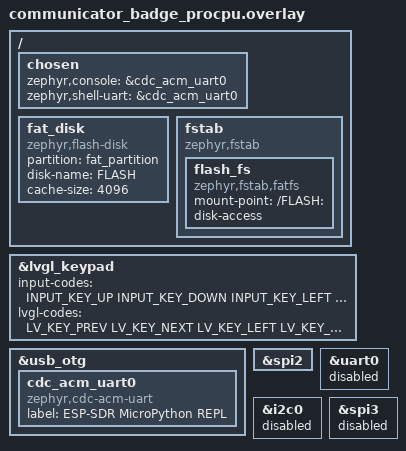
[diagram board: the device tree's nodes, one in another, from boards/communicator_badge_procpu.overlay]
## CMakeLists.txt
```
# SPDX-License-Identifier: GPL-3.0-or-later

cmake_minimum_required(VERSION 3.20.0)

# The radio is on the chip (radio.conf) except on an ESP32-P4, whose radio is the board's
# ESP32-C6 behind a link. Under sysbuild the board is not known here yet: sysbuild.cmake adds
# radio.conf there.
if(BOARD AND NOT BOARD MATCHES "/+esp32p4")
  list(APPEND EXTRA_CONF_FILE ${CMAKE_CURRENT_LIST_DIR}/radio.conf)
endif()

# MicroPython is built by its Zephyr module (CONFIG_MICROPYTHON, modules/micropython/zephyr)
# while find_package() configures Zephyr, and provides main(). The module reads two things
# from here: this app's C modules (cmod/) and, for the frozen manifests, the directory of the
# bundled apps' index. The index is written below, once Kconfig says which apps the board
# has; the module's configure-time pass over the manifest only needs the file to exist.
set(USER_C_MODULES ${CMAKE_CURRENT_LIST_DIR}/cmod)
set(MICROPY_MANIFEST_EGGS_INDEX_DIR ${CMAKE_BINARY_DIR}/eggs_index)
set(EGGS_INDEX ${MICROPY_MANIFEST_EGGS_INDEX_DIR}/eggs/__init__.py)
if(NOT EXISTS ${EGGS_INDEX})
  file(WRITE ${EGGS_INDEX} "INDEX = {}\n")
endif()

find_package(Zephyr REQUIRED HINTS $ENV{ZEPHYR_BASE})
project(esp_sdr_micropython)

# mpconfigport_esdr.h (CONFIG_MICROPY_CONFIGFILE), for the micropython library and its qstr scan.
zephyr_include_directories(src)

if(CONFIG_SOC_SERIES_ESP32C5)
  # The ESP32-C5: the REPL on the USB-Serial-JTAG console, MicroPython in the main thread
  # (the port's main()), its static heap in SRAM block 0 (sorted before the bank's snippet).
  zephyr_linker_sources(RAM_SECTIONS SORT_KEY app src/c5_low.ld)
elseif(CONFIG_SOC_SERIES_ESP32P4)
  # The ESP32-P4 (WHY2025 badge, ESP32-P4-Function-EV-Board): MicroPython in the main thread
  # (the port's main()), its heap in PSRAM (cmod/esdr_radio.c), the REPL on CDC-ACM and DFU
  # through the shared USB device on the OTG HS port, started by the port's mp_usbd_init()
  # (cmod/esdr_usb.c).
  include(${CMAKE_CURRENT_LIST_DIR}/../common/common.cmake)
  # The link to the radio and the USB glue, plain Zephyr code (outside MicroPython's include
  # path, whose assert.h hides the HAL's static_assert).
  target_sources(app PRIVATE cmod/esdr_remote.c cmod/esdr_hb.c cmod/esdr_mon.c cmod/esdr_usb.c
    cmod/esdr_gl.c)
  target_include_directories(app PRIVATE cmod ../osmosdr/src)
  # Its SDIO side, shared with the bridge app.
  include(${CMAKE_CURRENT_LIST_DIR}/../common/esdr_sdio_host.cmake)
  # The gapless stream's channelizer (cmod/esdr_gl.c): the fixed-point bank on PIE.
  include(${CMAKE_CURRENT_LIST_DIR}/../common/esdr_pfbq.cmake)
elseif(CONFIG_SOC_SERIES_ESP32)
  # The classic ESP32 (MCH2022 badge): the REPL on the console UART (the badge's RP2040 bridges
  # it to USB), MicroPython in the main thread (the port's main()), its heap in PSRAM
  # (cmod/esdr_radio.c), the radio on the chip behind the link's interface (cmod/esdr_local.c,
  # plain Zephyr code as esdr_remote.c is on the P4).
  target_sources(app PRIVATE cmod/esdr_local.c cmod/esdr_mon.c src/setjmp.S)
  target_include_directories(app PRIVATE cmod ../osmosdr/src)
  # The crystal calibration requests on the library (apps/common).
  include(${CMAKE_CURRENT_LIST_DIR}/../common/esdr_cal.cmake)
  # The ROM's setjmp spills windows by SYSCALL, as on the S3 (setjmp.S).
  zephyr_link_libraries("-Wl,--wrap=setjmp")
else()
  include(${CMAKE_CURRENT_LIST_DIR}/../common/common.cmake)

  target_sources(app PRIVATE src/boot.c src/setjmp.S src/usb_disks.c)
  # ff.h: usb_disks.c refreshes a FatFs volume without remounting it.
  target_link_libraries(app PRIVATE ELMFAT)
  # See setjmp.S.
  zephyr_link_libraries("-Wl,--wrap=setjmp")
  # boot.c runs the port's main() as real_main() in a thread of its own.
  set_property(SOURCE ${ZEPHYR_MICROPYTHON_MODULE_DIR}/ports/zephyr/main.c
               TARGET_DIRECTORY micropython APPEND PROPERTY COMPILE_DEFINITIONS main=real_main)
endif()

# What this app changes in the module's build (mpy_module.cmake).
include(${CMAKE_CURRENT_LIST_DIR}/mpy_module.cmake)
```

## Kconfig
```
# SPDX-License-Identifier: GPL-3.0-or-later

mainmenu "ESP-SDR MicroPython"

# The MicroPython symbols (CONFIG_MICROPYTHON, CONFIG_MICROPY_*) are the module's
# (modules/micropython/zephyr/Kconfig); these are the app's.
menu "ESP-SDR MicroPython"

config APP_EGGS
	string "Bundled apps"
	default ""
	help
	  The apps (folders of eggs/) the board's frozen manifest has, comma
	  separated; empty: all of them. The launcher's index lists these.

config APP_MP_STACK_SIZE
	int "MicroPython thread stack, bytes"
	default 16384
	help
	  In the SRAM above the ring banks (ESP_SDR_HIGH_RAM, about 38 KiB,
	  shared with the ring, the DAC stream and their threads).
	  Bounds the recursion depth, about 300 bytes per Python call. A
	  GUI export with LVGL peaked at 11.9 KiB.

config APP_HOME_CODE
	int "Key that goes home when held"
	default 1
	help
	  On boards whose keys drive LVGL as a keypad: the input code (Zephyr
	  input-event-codes.h) that, held 1.5 s, ends the running app and
	  shows the launcher. 1 is INPUT_KEY_ESC.

config APP_MP_PSRAM_HEAP_KB
	int "Python heap in PSRAM, KiB"
	default 5120
	help
	  Added to the internal heap at every start. Captures (file_sink) are
	  buffered here; the rest of the 8 MiB PSRAM is the Wi-Fi heap and the
	  transmit ring.

endmenu # ESP-SDR MicroPython

rsource "../common/Kconfig"

# USB device identity (VID, PID, strings) for the sample USB helper.
source "samples/subsys/usb/common/Kconfig.sample_usbd"

source "Kconfig.zephyr"
```

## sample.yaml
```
sample:
  name: ESP-SDR MicroPython
  description: >-
    MicroPython as the main program: on the XIAO ESP32S3 and the Communicator with the display,
    REPL on the USB CDC-ACM port; headless on the ESP32-C5-Zero, the bench's coordinator, REPL
    on USB-Serial-JTAG; on the WHY2025 badge's ESP32-P4 (the radio its ESP32-C6, REPL on
    CDC-ACM) and the MCH2022 badge's ESP32 (REPL on the console UART)
common:
  tags: esp-sdr
  build_only: true
tests:
  sample.esp_sdr.micropython:
    sysbuild: true
    platform_allow:
      - xiao_esp32s3/esp32s3/procpu
      - communicator_badge/esp32s3/procpu
    integration_platforms:
      - xiao_esp32s3/esp32s3/procpu
  sample.esp_sdr.micropython.c5:
    platform_allow:
      - waveshare_esp32c5_zero/esp32c5/hpcore
    integration_platforms:
      - waveshare_esp32c5_zero/esp32c5/hpcore
  sample.esp_sdr.micropython.p4:
    platform_allow:
      - why2025_badge/esp32p4/hpcore
      - esp32p4_function_ev_board/esp32p4/hpcore
    integration_platforms:
      - why2025_badge/esp32p4/hpcore
      - esp32p4_function_ev_board/esp32p4/hpcore
  sample.esp_sdr.micropython.mch2022:
    platform_allow:
      - mch2022/esp32/procpu
    integration_platforms:
      - mch2022/esp32/procpu
```

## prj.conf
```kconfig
# MicroPython (modules/micropython/ports/zephyr/prj.conf), on every board; the radio where it
# is on the chip in radio.conf; what both S3 boards add is in socs/esp32s3_procpu.conf (USB,
# PSRAM, display, the ring), what one board adds in boards/<board>.conf (the XIAO S3: SD card;
# the C5: the diagnostic-bus ring and the paced transmitter; the P4: display, keyboard, PSRAM).
CONFIG_POLL=y
CONFIG_REBOOT=y
# The port's zsensor module includes the sensor API; no sensor, no code.
CONFIG_SENSOR=y
CONFIG_HEAP_MEM_POOL_IGNORE_MIN=y

# REPL input comes from the console driver's receive hook (src/zephyr_getchar.c), output
# goes to the console UART directly.
CONFIG_SERIAL=y
CONFIG_STDOUT_CONSOLE=y
CONFIG_CONSOLE_HANDLER=y
CONFIG_UART_CONSOLE_DEBUG_SERVER_HOOKS=y
CONFIG_UART_INTERRUPT_DRIVEN=y
CONFIG_UART_USE_RUNTIME_CONFIGURE=y

# MicroPython's Zephyr module builds the port as the micropython library, which provides
# main(); paths are relative to this directory. The boards set the heap
# (CONFIG_MICROPY_HEAP_SIZE) and those without a display their manifest.
CONFIG_MICROPYTHON=y
CONFIG_MICROPY_CONFIGFILE="mpconfigport_esdr.h"
CONFIG_MICROPY_FROZEN_MODULES=y
CONFIG_MICROPY_FROZEN_MANIFEST="manifest.py"
CONFIG_MICROPY_CONFIG_ROM_LEVEL_EXTRA_FEATURES=y

# Nothing may print into the REPL: no log backend.
CONFIG_LOG=n

CONFIG_RESET_ON_FATAL_ERROR=y


# MicroPython's Zephyr port (machine_spi.c, built wherever SPI is on: both boards)
# still uses SPI_OP_MODE_MASTER, whose deprecation warning -Werror (twister, CI) makes fatal.
CONFIG_WARN_DEPRECATED=n
```

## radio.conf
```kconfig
# SPDX-License-Identifier: GPL-3.0-or-later

# The radio on the chip itself, for every board but the WHY2025 badge's ESP32-P4 (CMakeLists.txt):
# the Wi-Fi driver brings it up at boot; nothing may scan or connect.
CONFIG_NETWORKING=y
CONFIG_WIFI=y
CONFIG_ESP32_WIFI_STA_POWER_SAVE_NONE=y
# No IP traffic: the network stack only carries the Wi-Fi driver, minimal.
CONFIG_NET_IPV6=n
CONFIG_NET_IPV4=y
CONFIG_NET_PKT_RX_COUNT=4
CONFIG_NET_PKT_TX_COUNT=4
CONFIG_NET_BUF_RX_COUNT=8
CONFIG_NET_BUF_TX_COUNT=8
CONFIG_NET_RX_STACK_SIZE=1024
CONFIG_NET_L2_WIFI_SHELL=n

CONFIG_ESP_SDR=y
```

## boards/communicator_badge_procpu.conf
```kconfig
# The Hackaday Communicator badge with its display and keyboard (socs/esp32s3_procpu.conf has
# what both ESP32-S3 boards share).

# No GDMA for the display SPI (overlay): DRAM ends at the ring banks.
CONFIG_DMA=n
# LVGL reads the keyboard every refresh; 2 queued keys fit the DRAM, 4 did not.
CONFIG_LV_Z_KEYPAD_INPUT_MSGQ_COUNT=2
```

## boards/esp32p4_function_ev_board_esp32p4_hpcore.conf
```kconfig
# SPDX-License-Identifier: GPL-3.0-or-later
#
# The ESP32-P4-Function-EV-Board's ESP32-P4: MicroPython without a display, the REPL and DFU on
# the USB 2.0 OTG HS port, the Python heap in PSRAM. No radio on the chip (no radio.conf): the
# board's ESP32-C6 is the radio, over SDIO. prj.conf has what every board shares.

CONFIG_MAIN_STACK_SIZE=32768
# The port's own heap in SRAM is a token; esdr_port_init() adds the PSRAM heap.
CONFIG_MICROPY_HEAP_SIZE=16384
CONFIG_APP_MP_PSRAM_HEAP_KB=4096
CONFIG_MICROPY_FROZEN_MANIFEST="manifest_headless.py"
CONFIG_APP_EGGS="datalink"
CONFIG_FPU=y
# As on the WHY2025 badge: the SoC turns the FPU on without sharing, and the channelizer's
# thread (esdr_gl.c) preempts MicroPython in float code.
CONFIG_FPU_SHARING=y
# PSRAM (on the WHY2025 badge the display brings it in).
CONFIG_ESP_SPIRAM=y
CONFIG_HEAP_MEM_POOL_SIZE=32768

# The FAT volume /FLASH: and the SD card /SD: (overlay).
CONFIG_FLASH_MAP=y
CONFIG_FILE_SYSTEM=y
CONFIG_FAT_FILESYSTEM_ELM=y
CONFIG_DISK_DRIVER_FLASH=y
CONFIG_DISK_DRIVER_SDMMC=y
CONFIG_FS_FATFS_NUM_FILES=8
CONFIG_FS_FATFS_NUM_DIRS=4
CONFIG_FS_FATFS_LFN=y
CONFIG_FS_FATFS_LFN_MODE_BSS=y
CONFIG_FS_FATFS_MAX_LFN=64
CONFIG_FS_FATFS_EXFAT=y

CONFIG_GPIO=y
# os.urandom (the data link's node id); on the radio chips Wi-Fi brings the TRNG in.
CONFIG_ENTROPY_GENERATOR=y

# The radio's link: SDIO function 1 to the C6 on sdhc1 (cmod/esdr_remote.c).
CONFIG_SDIO_STACK=y
# The SDIO reader polls the radio's byte counter; idle, it sleeps a tick: 100 us, not 1 ms
# (at 2 MS/s the radio fills a 4 KB block in 1 ms).
CONFIG_SYS_CLOCK_TICKS_PER_SEC=10000

# USB device on the OTG HS port: the REPL on CDC-ACM, DFU with sysbuild/MCUboot; the port's
# mp_usbd_init() starts it (cmod/esdr_usb.c).
CONFIG_USB_DEVICE_STACK_NEXT=y
CONFIG_UDC_DRIVER_HIGH_SPEED_SUPPORT_ENABLED=y
CONFIG_SAMPLE_USBD_PRODUCT="ESP-SDR MicroPython"
# Same PID as the other apps (host udev rules).
CONFIG_SAMPLE_USBD_PID=0x0005
CONFIG_USBD_CDC_ACM_CLASS=y
CONFIG_CDC_ACM_SERIAL_INITIALIZE_AT_BOOT=n
CONFIG_UART_LINE_CTRL=y
CONFIG_USBD_THREAD_STACK_SIZE=2048

# The shell has no serial backend (nothing may print into the REPL): its dummy backend serves
# esdr.shell(), for "mcuboot confirm" after west dfu and "kernel uptime".
CONFIG_SHELL=y
CONFIG_SHELL_BACKEND_SERIAL=n
CONFIG_SHELL_BACKEND_DUMMY=y
CONFIG_KERNEL_SHELL=y
CONFIG_SHELL_STACK_SIZE=2048
CONFIG_SHELL_CMD_BUFF_SIZE=128
CONFIG_SHELL_HISTORY=n
CONFIG_DEVICE_SHELL=n
CONFIG_DATE_SHELL=n
CONFIG_MCUBOOT_SHELL=y
# As on the WHY2025 badge: west dfu confirms from the REPL (esdr.shell), a hang resets the
# board, and on one CPU the USB threads preempt MicroPython but not the system work queue.
CONFIG_APP_TRIAL_WATCHDOG=n
CONFIG_APP_LIVENESS_WATCHDOG=y
CONFIG_USBD_THREAD_PREEMPTIBLE=y
CONFIG_UDC_DWC2_THREAD_PREEMPTIBLE=y
CONFIG_MAIN_THREAD_PRIORITY=10
CONFIG_USBD_DFU_TRANSFER_SIZE=1024
CONFIG_UDC_BUF_POOL_SIZE=4096
```

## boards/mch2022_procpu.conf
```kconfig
# SPDX-License-Identifier: GPL-3.0-or-later
#
# The MCH2022 badge's ESP32: MicroPython with LVGL on the 320x240 display, the buttons, the
# REPL on the console UART (the RP2040's first USB serial port), the Python heap in PSRAM, the
# radio on the chip (bursts, cmod/esdr_local.c). prj.conf has what every board shares,
# radio.conf the radio.

# MicroPython runs in the main thread (the port's own start); a GUI export with LVGL peaked at
# 11.9 KiB on the S3.
CONFIG_MAIN_STACK_SIZE=16384
# The port's own heap in SRAM is a token; esdr_port_init() adds the PSRAM heap (of the 4 MiB
# the ESP32 maps).
CONFIG_MICROPY_HEAP_SIZE=8192
CONFIG_ESP_SPIRAM=y
CONFIG_APP_MP_PSRAM_HEAP_KB=3072
CONFIG_FPU=y
CONFIG_FPU_SHARING=y
# The Wi-Fi driver allocates from the PSRAM heap, with some 25 KB of the kernel heap (the
# minimum it asks for then); the radio only listens (promiscuous, no traffic): a few buffers.
CONFIG_ESP_WIFI_HEAP_SPIRAM=y
CONFIG_HEAP_MEM_POOL_SIZE=26624
CONFIG_ESP32_WIFI_STATIC_RX_BUFFER_NUM=2
CONFIG_ESP32_WIFI_DYNAMIC_RX_BUFFER_NUM=4
CONFIG_ESP32_WIFI_DYNAMIC_TX_BUFFER_NUM=4
CONFIG_ESP32_WIFI_AMPDU_RX_ENABLED=n
CONFIG_ESP32_WIFI_AMPDU_TX_ENABLED=n
# The capture bank is SRAM1, where .noinit would spill otherwise.
CONFIG_ESP32_REGION_1_NOINIT=n

# The FAT volume /FLASH: and the SD card /SD: (overlay).
CONFIG_FLASH_MAP=y
CONFIG_FILE_SYSTEM=y
CONFIG_FAT_FILESYSTEM_ELM=y
CONFIG_DISK_DRIVER_FLASH=y
CONFIG_DISK_DRIVER_SDMMC=y
CONFIG_FS_FATFS_NUM_FILES=8
CONFIG_FS_FATFS_NUM_DIRS=4
CONFIG_FS_FATFS_LFN=y
CONFIG_FS_FATFS_LFN_MODE_BSS=y
CONFIG_FS_FATFS_MAX_LFN=64

CONFIG_GPIO=y

# The buttons through the RP2040 (an LVGL keypad), its backlight.
CONFIG_I2C=y
CONFIG_MFD=y
CONFIG_INPUT=y
CONFIG_INPUT_MODE_SYNCHRONOUS=y
CONFIG_APP_HOME_CODE=102

# LVGL on the ILI9341 (big-endian RGB565, which LVGL renders as such: no LV_COLOR_16_SWAP), its
# heap in the MicroPython heap, its draw buffer in SRAM: the display's SPI DMA cannot read PSRAM.
CONFIG_DISPLAY=y
CONFIG_LVGL=y
CONFIG_LV_Z_MEM_POOL_MICROPYTHON=y
CONFIG_LV_Z_AUTO_INIT=n
CONFIG_LV_Z_BUFFER_ALLOC_STATIC=y
CONFIG_LV_Z_VDB_SIZE=10
CONFIG_LV_Z_DOUBLE_VDB=n
CONFIG_LV_DEF_REFR_PERIOD=20
```

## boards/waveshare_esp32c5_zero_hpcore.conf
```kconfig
# The Waveshare ESP32-C5-Zero as the bench's coordinator: MicroPython headless (no display) on
# the USB-Serial-JTAG console, no PSRAM; receive through the diagnostic-bus ring, transmit
# through the CPU-paced TX DC path; the bench's RF switch from Python (rfswitch). prj.conf has
# what every board shares.

# The U.FL port, which goes to the RF switch, instead of the chip antenna.
CONFIG_WAVESHARE_ESP32C5_ZERO_EXT_ANTENNA=y

# MicroPython runs in the main thread (the port's own start): a GRC export's console loop with
# the packet link nests about 25 Python calls; 10 KiB overflowed.
CONFIG_MAIN_STACK_SIZE=16384
# The port's heap, in SRAM block 0 (src/c5_low.ld); esdr_port_init() adds the upper half of SRAM
# block 1 and most of the libc heap in block 2, which nothing else here needs (esdr_c5.c).
CONFIG_MICROPY_HEAP_SIZE=20480
CONFIG_MICROPY_FROZEN_MANIFEST="manifest_c5.py"
# The bundled apps that run headless on this radio.
CONFIG_APP_EGGS="datalink"

CONFIG_ESP_SDR_RFTEST=y
# Streams come from the ring or the paced receiver, not from decimated bursts.
CONFIG_ESP_SDR_RX_DECIM=n
CONFIG_ESP_SDR_PACED=y
CONFIG_ESP_SDR_DIAG=y

# The Wi-Fi driver's buffers come from the system heap (no PSRAM): fewer of them.
CONFIG_ESP32_WIFI_STATIC_RX_BUFFER_NUM=4
CONFIG_ESP32_WIFI_DYNAMIC_RX_BUFFER_NUM=8
CONFIG_ESP32_WIFI_DYNAMIC_TX_BUFFER_NUM=8
CONFIG_ESP32_WIFI_MGMT_SBUF_NUM=8

# machine.Pin for the RF switch.
CONFIG_GPIO=y

# The kernel heap, which the Wi-Fi driver allocates from here (its default asks for 55 KiB):
# 24 KiB was too little for it to start.
CONFIG_HEAP_MEM_POOL_SIZE=40960
```

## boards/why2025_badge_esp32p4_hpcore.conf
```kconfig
# SPDX-License-Identifier: GPL-3.0-or-later
#
# The WHY2025 badge's ESP32-P4: MicroPython with LVGL on the 720x720 display, the keyboard,
# the REPL on the console UART (the CH340), the Python heap in PSRAM. No radio on the chip
# (no radio.conf): the badge's ESP32-C6 is the radio. prj.conf has what every board shares.

# MicroPython runs in the main thread (the port's own start); a GUI export with LVGL peaked at
# 11.9 KiB on the S3.
CONFIG_MAIN_STACK_SIZE=32768
# The port's own heap in SRAM is a token; esdr_port_init() adds the PSRAM heap.
CONFIG_MICROPY_HEAP_SIZE=16384
CONFIG_APP_MP_PSRAM_HEAP_KB=16384
CONFIG_MICROPY_FROZEN_MANIFEST="manifest.py"
CONFIG_FPU=y
# The SoC turns the FPU on without sharing: a thread that preempts another in float code (the
# channelizer, esdr_gl.c, above MicroPython) would leave its registers behind. Lazy switching
# (Zephyr decodes the trapping instruction from mtval, which the P4 fills).
CONFIG_FPU_SHARING=y
CONFIG_HEAP_MEM_POOL_SIZE=32768

# The FAT volume /FLASH: and the SD card /SD: (overlay).
CONFIG_FLASH_MAP=y
CONFIG_FILE_SYSTEM=y
CONFIG_FAT_FILESYSTEM_ELM=y
CONFIG_DISK_DRIVER_FLASH=y
CONFIG_DISK_DRIVER_SDMMC=y
CONFIG_FS_FATFS_NUM_FILES=8
CONFIG_FS_FATFS_NUM_DIRS=4
CONFIG_FS_FATFS_LFN=y
CONFIG_FS_FATFS_LFN_MODE_BSS=y
CONFIG_FS_FATFS_MAX_LFN=64
CONFIG_FS_FATFS_EXFAT=y

CONFIG_GPIO=y
# os.urandom (the data link's node id); on the radio chips Wi-Fi brings the TRNG in.
CONFIG_ENTROPY_GENERATOR=y

# LVGL on the DSI display (framebuffers in PSRAM), its heap in the MicroPython heap, its draw
# buffers in SRAM (static: drawing into PSRAM ones and transposing out of them for the turned
# panel cost a third more); the keyboard as an LVGL keypad.
CONFIG_DISPLAY=y
CONFIG_INPUT=y
CONFIG_INPUT_MODE_SYNCHRONOUS=y
CONFIG_LVGL=y
CONFIG_LV_Z_MEM_POOL_MICROPYTHON=y
CONFIG_LV_Z_AUTO_INIT=n
CONFIG_LV_Z_BUFFER_ALLOC_STATIC=y
CONFIG_LV_Z_VDB_SIZE=6
CONFIG_LV_Z_DOUBLE_VDB=y
CONFIG_LV_DEF_REFR_PERIOD=20

# The radio's link (UART1 at 5 Mbaud): an interrupt per 96 received bytes, not per byte (the
# console's UART shares the setting, harmlessly).
CONFIG_UART_ESP32_RX_FIFO_THRESH=0x60
# The transmit FIFO wakes the link's writer with 64 bytes (128 us) still to send.
CONFIG_UART_ESP32_TX_FIFO_THRESH=0x40
# The radio's link: SDIO function 1 to the C6 on sdhc1 (cmod/esdr_remote.c).
CONFIG_SDIO_STACK=y
# The SDIO reader polls the radio's byte counter; idle, it sleeps a tick: 100 us, not 1 ms
# (at 2 MS/s the radio fills a 4 KB block in 1 ms).
CONFIG_SYS_CLOCK_TICKS_PER_SEC=10000

# USB device on USB-C J8 (OTG HS): the REPL on CDC-ACM, DFU with sysbuild/MCUboot; the port's
# mp_usbd_init() starts it (cmod/esdr_usb.c).
CONFIG_USB_DEVICE_STACK_NEXT=y
CONFIG_UDC_DRIVER_HIGH_SPEED_SUPPORT_ENABLED=y
CONFIG_SAMPLE_USBD_PRODUCT="ESP-SDR MicroPython"
# Same PID as the other apps (host udev rules).
CONFIG_SAMPLE_USBD_PID=0x0005
CONFIG_USBD_CDC_ACM_CLASS=y
CONFIG_CDC_ACM_SERIAL_INITIALIZE_AT_BOOT=n
CONFIG_UART_LINE_CTRL=y
CONFIG_USBD_THREAD_STACK_SIZE=2048

# The shell has no serial backend (nothing may print into the REPL): its dummy backend serves
# esdr.shell(), for "mcuboot confirm" after west dfu and "kernel uptime".
CONFIG_SHELL=y
CONFIG_SHELL_BACKEND_SERIAL=n
CONFIG_SHELL_BACKEND_DUMMY=y
CONFIG_KERNEL_SHELL=y
CONFIG_SHELL_STACK_SIZE=2048
CONFIG_SHELL_CMD_BUFF_SIZE=128
CONFIG_SHELL_HISTORY=n
CONFIG_DEVICE_SHELL=n
CONFIG_DATE_SHELL=n
CONFIG_MCUBOOT_SHELL=y
# As on the S3: west dfu confirms from the REPL (esdr.shell), so no trial revert, but a hang
# resets the board.
CONFIG_APP_TRIAL_WATCHDOG=n
CONFIG_APP_LIVENESS_WATCHDOG=y
# One CPU: the USB threads preempt MicroPython (main, 10) but not the system work queue, which
# feeds the liveness watchdog (cooperative, the USB thread held it off through a DFU download
# until the watchdog reset the board).
CONFIG_USBD_THREAD_PREEMPTIBLE=y
CONFIG_UDC_DWC2_THREAD_PREEMPTIBLE=y
CONFIG_MAIN_THREAD_PRIORITY=10
# DFU in 1 KiB blocks (the most the class takes): each block costs a status round trip. The
# request pool holds one such control transfer next to CDC-ACM's 512-byte bulk buffers.
CONFIG_USBD_DFU_TRANSFER_SIZE=1024
CONFIG_UDC_BUF_POOL_SIZE=4096
```

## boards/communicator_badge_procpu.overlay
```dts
/*
 * SPDX-License-Identifier: GPL-3.0-or-later
 *
 * Hackaday Communicator badge: the board's 428x142 display and keyboard, no SD card.
 */

#include <zephyr/dt-bindings/input/input-event-codes.h>
#include <zephyr/dt-bindings/lvgl/lvgl.h>

/ {
	chosen {
		zephyr,console = &cdc_acm_uart0;
		zephyr,shell-uart = &cdc_acm_uart0;
	};

	/* The FAT volume "FLASH", mounted at /FLASH:, shared with the USB host. */
	fat_disk: fat_disk {
		compatible = "zephyr,flash-disk";
		partition = <&fat_partition>;
		disk-name = "FLASH";
		cache-size = <4096>;
	};

	fstab {
		compatible = "zephyr,fstab";

		flash_fs: flash_fs {
			compatible = "zephyr,fstab,fatfs";
			mount-point = "/FLASH:";
			disk-access;
		};
	};
};

/*
 * The keyboard drives LVGL as the knob does: up and down move the focus, left and right
 * change the focused value, Enter selects, Esc goes back (held 1.5 s: the launcher).
 */
&lvgl_keypad {
	input-codes = <INPUT_KEY_UP INPUT_KEY_DOWN INPUT_KEY_LEFT INPUT_KEY_RIGHT
		       INPUT_KEY_ENTER INPUT_KEY_ESC INPUT_KEY_BACKSPACE INPUT_KEY_TAB>;
	lvgl-codes = <LV_KEY_PREV LV_KEY_NEXT LV_KEY_LEFT LV_KEY_RIGHT
		      LV_KEY_ENTER LV_KEY_ESC LV_KEY_BACKSPACE LV_KEY_NEXT>;
};

zephyr_udc0: &usb_otg {
	status = "okay";

	/* The REPL's console while OTG owns the USB port. */
	cdc_acm_uart0: cdc_acm_uart0 {
		compatible = "zephyr,cdc-acm-uart";
		label = "ESP-SDR MicroPython REPL";
	};
};

#include "partitions.dtsi"

/*
 * The display without GDMA: its driver and DMA paths do not fit in the DRAM below the
 * receiver's ring banks.
 */
&spi2 {
	/delete-property/ dma-enabled;
	/delete-property/ dmas;
	/delete-property/ dma-names;
};

/* Unused here, and their drivers' RAM does not fit: UART0 (J7), the SAO bus, the LoRa module. */
&uart0 {
	status = "disabled";
};

&i2c0 {
	status = "disabled";
};

&spi3 {
	status = "disabled";
};
```

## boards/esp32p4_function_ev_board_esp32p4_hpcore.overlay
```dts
/*
 * SPDX-License-Identifier: GPL-3.0-or-later
 *
 * ESP32-P4-Function-EV-Board, ESP32-P4: no display; the REPL on CDC-ACM and DFU on the USB 2.0
 * OTG HS port (USB-C); boot messages on the USB-UART (UART0); the radio is the board's
 * ESP32-C6 on SDIO.
 */

/ {
	chosen {
		zephyr,console = &cdc_acm_uart0;
		zephyr,shell-uart = &cdc_acm_uart0;
		/* The radio: the C6's osmosdr_serial (cmod/esdr_remote.c) over SDIO. */
		esdr,link-sdio = &sdhc1;
		/delete-property/ zephyr,display;
		/delete-property/ zephyr,touch;
	};

	/* GPIO54 is the ESP32-C6's enable (cmod/esdr_usb.c drives it). */
	zephyr,user {
		c6-enable-gpios = <&gpio1 22 GPIO_ACTIVE_HIGH>;
	};

	/* The FAT volume "FLASH", mounted at /FLASH:, and the SD card at /SD:. */
	fat_disk: fat_disk {
		compatible = "zephyr,flash-disk";
		partition = <&fat_partition>;
		disk-name = "FLASH";
		cache-size = <4096>;
	};

	fstab {
		compatible = "zephyr,fstab";

		flash_fs: flash_fs {
			compatible = "zephyr,fstab,fatfs";
			mount-point = "/FLASH:";
			disk-access;
		};

		/* The microSD card (sdhc0), if one mounts; never formatted (esdr_radio.c sets
		 * FS_MOUNT_FLAG_NO_FORMAT).
		 */
		sd_fs: sd_fs {
			compatible = "zephyr,fstab,fatfs";
			mount-point = "/SD:";
			disk-access;
		};
	};
};

/* The ESP32-C6 runs the radio firmware, not esp-hosted, whose driver would reset it. */
&esp_hosted_mcu {
	status = "disabled";
};

zephyr_udc0: &usb_otg {
	status = "okay";
	/*
	 * An IN endpoint is bulk capable only with a FIFO of a whole high-speed packet (512 bytes,
	 * 128 words). The SoC gives that to one, which CDC-ACM's notification endpoint takes
	 * first: its bulk IN endpoint needs a second.
	 */
	g-tx-fifo-size = <128 128 64 64 64 64 64>;

	/* The REPL's console. */
	cdc_acm_uart0: cdc_acm_uart0 {
		compatible = "zephyr,cdc-acm-uart";
		label = "ESP-SDR MicroPython REPL";
	};
};

#include "partitions_p4.dtsi"
```

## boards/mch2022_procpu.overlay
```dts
/*
 * SPDX-License-Identifier: GPL-3.0-or-later
 *
 * MCH2022 badge: the 320x240 display and the buttons; the REPL on the console UART, which the
 * badge's RP2040 bridges to its first USB serial port; the radio on the chip.
 */

#include <zephyr/dt-bindings/input/input-event-codes.h>
#include <zephyr/dt-bindings/lvgl/lvgl.h>

/ {
	/* The FAT volume "FLASH", mounted at /FLASH:, and the SD card at /SD:. */
	fat_disk: fat_disk {
		compatible = "zephyr,flash-disk";
		partition = <&fat_partition>;
		disk-name = "FLASH";
		cache-size = <4096>;
	};

	fstab {
		compatible = "zephyr,fstab";

		flash_fs: flash_fs {
			compatible = "zephyr,fstab,fatfs";
			mount-point = "/FLASH:";
			disk-access;
		};

		/* The microSD card, if one mounts; never formatted (esdr_board.c). */
		sd_fs: sd_fs {
			compatible = "zephyr,fstab,fatfs";
			mount-point = "/SD:";
			disk-access;
		};
	};
};

/*
 * The buttons drive LVGL as a keypad: the joystick's up and down move the focus, left and right
 * change the focused value, A and the joystick's press select, B goes back; HOME held 1.5 s goes
 * to the launcher (CONFIG_APP_HOME_CODE).
 */
&lvgl_keypad {
	input-codes = <INPUT_KEY_UP INPUT_KEY_DOWN INPUT_KEY_LEFT INPUT_KEY_RIGHT
		       INPUT_KEY_ENTER INPUT_BTN_THUMBL INPUT_KEY_BACK INPUT_KEY_HOME>;
	lvgl-codes = <LV_KEY_PREV LV_KEY_NEXT LV_KEY_LEFT LV_KEY_RIGHT
		      LV_KEY_ENTER LV_KEY_ENTER LV_KEY_ESC LV_KEY_ESC>;
};

#include "partitions_mch2022.dtsi"

/*
 * The FPGA as display controller and spectrum engine (the fpga module, qtgui's waterfall and
 * frequency sinks); the bitstream comes with -DCONFIG_ESDR_FPGA_IMAGE=<gateware build>/top.bin.
 * Without one the panel stays on SPI and the sinks draw in software.
 */
#include "../../../dts/esdr/mch2022_fpga.dtsi"
```

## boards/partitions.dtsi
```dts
/*
 * SPDX-License-Identifier: GPL-3.0-or-later
 *
 * Flash layout of this application, for the application and its MCUboot
 * (sysbuild/mcuboot.overlay), which must agree on it: Espressif's 4 MB default
 * table (two 1792 KiB slots, MicroPython with LVGL needs more than the
 * 1344 KiB of the XIAO ESP32S3's AMP table) instead of the board's table,
 * whose APP CPU slots go unused (the S3 runs SMP), and the 4 MB above it as the
 * FAT volume "FLASH", on any S3 board with at least 8 MB of flash. The volume
 * stays where apps/multiapp keeps it.
 */

&flash0 {
	/delete-node/ partitions;
};

#include <espressif/partitions_0x0_default_4M.dtsi>

&flash0 {
	partitions {
		fat_partition: partition@400000 {
			compatible = "zephyr,mapped-partition";
			label = "fat";
			reg = <0x400000 DT_SIZE_M(4)>;
		};
	};
};
```

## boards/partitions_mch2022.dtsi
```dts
/*
 * SPDX-License-Identifier: GPL-3.0-or-later
 *
 * The MCH2022 badge's flash: the application in the lower 8 MB (Espressif's 8 MB table: MCUboot
 * at 0x1000 and two 3840 KiB slots), the upper 8 MB the FAT volume.
 */

&flash0 {
	/delete-node/ partitions;
};

#include <espressif/partitions_0x1000_default_8M.dtsi>

&flash0 {
	partitions {
		fat_partition: partition@800000 {
			compatible = "zephyr,mapped-partition";
			label = "fat";
			reg = <0x800000 DT_SIZE_M(8)>;
		};
	};
};
```

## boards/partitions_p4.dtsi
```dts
/*
 * SPDX-License-Identifier: GPL-3.0-or-later
 *
 * The 16 MB flash of an ESP32-P4 board (the WHY2025 badge, the ESP32-P4-Function-EV-Board):
 * MCUboot at 0x2000 and the application in the lower 8 MB (Espressif's 8 MB table: two 3840 KiB
 * slots), the upper 8 MB the FAT volume. The application and MCUboot
 * (sysbuild/mcuboot_p4.overlay) share it.
 */

&flash0 {
	/delete-node/ partitions;
};

#include <espressif/partitions_0x2000_default_8M.dtsi>

&flash0 {
	partitions {
		fat_partition: partition@800000 {
			compatible = "zephyr,mapped-partition";
			label = "fat";
			reg = <0x800000 DT_SIZE_M(8)>;
		};
	};
};
```

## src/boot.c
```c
/*
 * SPDX-License-Identifier: GPL-3.0-or-later
 *
 * Boot glue for MicroPython as the main program. The shared USB device (CDC-ACM console the
 * REPL talks to, DFU, watchdog) starts from here. The port's main(), compiled as real_main()
 * (CMakeLists.txt), runs in its own thread on CPU 0 with its stack in the SRAM above the ring
 * banks: internal RAM, which flash access needs (doc/hardware-quirks.md, Memory), but outside
 * the DRAM image, which must end below the ring banks. esdr_port_init() points MicroPython's
 * stack check at that stack.
 */

#include <zephyr/init.h>
#include <zephyr/kernel.h>
#include <zephyr/logging/log.h>

#include <esp_sdr/esp_sdr.h>

#include "app_cpu.h"
#include "app_usb.h"

LOG_MODULE_REGISTER(boot, LOG_LEVEL_INF);

/* The port's main() (main.c), which also hooks the REPL's input into the console driver. */
int real_main(void);

/* The port's real_main() calls this at every soft reset; app_usb.h has started USB once. */
int mp_usbd_init(void)
{
	return 0;
}

ESP_SDR_HIGH_STACK_DEFINE(mp_stack, CONFIG_APP_MP_STACK_SIZE);
static struct k_thread mp_thread;

static void mp_entry(void *a, void *b, void *c)
{
	ARG_UNUSED(a);
	ARG_UNUSED(b);
	ARG_UNUSED(c);
	(void)real_main();
}

static void repin_handler(struct k_work *work)
{
	ARG_UNUSED(work);
	/* The USB threads exist by now. */
	app_cpu_pin_system_threads(0);
}

static K_WORK_DELAYABLE_DEFINE(repin_work, repin_handler);

static int boot(void)
{
	app_cpu_pin_system_threads(0);
	if (app_usb_init() != 0) {
		LOG_ERR("USB init failed");
	}
	k_work_schedule(&repin_work, K_MSEC(500));
	return 0;
}

SYS_INIT(boot, APPLICATION, 99);

int main(void)
{
	k_thread_create(&mp_thread, mp_stack, K_KERNEL_STACK_SIZEOF(mp_stack), mp_entry, NULL,
			NULL, NULL, CONFIG_MAIN_THREAD_PRIORITY, K_FP_REGS, K_FOREVER);
	k_thread_name_set(&mp_thread, "micropython");
#if defined(CONFIG_SCHED_CPU_MASK)
	/* CPU 1 belongs to the receive ring while it runs. */
	if (arch_num_cpus() > 1) {
		k_thread_cpu_pin(&mp_thread, 0);
	}
#endif
	k_thread_start(&mp_thread);
	return 0;
}
```

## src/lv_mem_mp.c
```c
/*
 * SPDX-License-Identifier: GPL-3.0-or-later
 *
 * LVGL's allocator on the MicroPython heap (LV_STDLIB_MICROPYTHON), in place of LVGL's
 * src/stdlib/micropython/lv_mem_core_micropython.c, whose m_malloc() raises MemoryError: the
 * longjmp would cross LVGL's C frames and leave its event list and guards behind. These return
 * NULL, as LVGL expects, also while the GC is locked (finalisers).
 */

#include <lvgl.h>

#include "py/gc.h"
#include "py/misc.h"

void lv_mem_init(void)
{
}

void lv_mem_deinit(void)
{
}

lv_mem_pool_t lv_mem_add_pool(void *mem, size_t bytes)
{
	LV_UNUSED(mem);
	LV_UNUSED(bytes);
	return NULL;
}

void lv_mem_remove_pool(lv_mem_pool_t pool)
{
	LV_UNUSED(pool);
}

void *lv_malloc_core(size_t size)
{
	return m_malloc_maybe(size);
}

void *lv_realloc_core(void *p, size_t new_size)
{
	return m_realloc_maybe(p, new_size, true);
}

void lv_free_core(void *p)
{
	m_free(p);
}

void lv_mem_monitor_core(lv_mem_monitor_t *mon_p)
{
	LV_UNUSED(mon_p);
}

lv_result_t lv_mem_test_core(void)
{
	return LV_RESULT_OK;
}
```

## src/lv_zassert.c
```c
/*
 * SPDX-License-Identifier: GPL-3.0-or-later
 *
 * The LVGL binding (lv_mp.c) wraps every function the headers it parses declare. Zephyr's
 * sys/zassert.h declares zassert_post_action() whatever CONFIG_ASSERT says, but
 * subsys/debug/zassert defines it only with assertions on; this is it for builds without them,
 * doing what a failed assertion does there.
 */

#include <zephyr/kernel.h>
#include <zephyr/sys/__assert.h>

FUNC_NORETURN void zassert_post_action(const char *file, unsigned int line)
{
	ARG_UNUSED(file);
	ARG_UNUSED(line);
	k_panic();
	CODE_UNREACHABLE;
}
```

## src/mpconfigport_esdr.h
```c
/*
 * SPDX-License-Identifier: GPL-3.0-or-later
 *
 * The port's configuration (modules/micropython/ports/zephyr/mpconfigport.h) plus what
 * the ESP32-S3 and this app need.
 */

#include "mpconfigport.h"

/*
 * The Xtensa windowed ABI: the port has no assembler non-local return for it, but this
 * setjmp spills the register windows to the stack (setjmp.S; as ports/esp32 relies on), which is
 * also what the GC needs to see the live registers on the stack.
 */
#define MICROPY_NLR_SETJMP                  (1)
#define MICROPY_GCREGS_SETJMP               (1)

#define MICROPY_PY_BUILTINS_INPUT           (1)

/* The port's 512 bytes left too little C stack below the limit for printing the traceback of a
 * deep recursion (it overflowed the ESP32-C5's main stack). */
#undef MICROPY_STACK_CHECK_MARGIN
#define MICROPY_STACK_CHECK_MARGIN          (1024)

/* GRC exports carry complex constants (offsets, multiply_const_cc, vector_source_c data). */
#undef MICROPY_PY_BUILTINS_COMPLEX
#define MICROPY_PY_BUILTINS_COMPLEX         (1)

/*
 * The Python heap: CONFIG_MICROPY_HEAP_SIZE of internal RAM, which the receive ring leaves
 * little of, plus CONFIG_APP_MP_PSRAM_HEAP_KB of PSRAM that esdr_port_init() adds at every
 * start (cmod/modesdr.c). esdr_port_deinit() stops the radio before a soft reset frees it.
 */
#define MICROPY_GC_SPLIT_HEAP               (1)
void esdr_port_init(void);
void esdr_port_deinit(void);
/* The port's main() sets a collection threshold of an eighth of its static heap, a few bytes
 * to a few KiB here, where most of the heap is what esdr_port_init() adds: none, as gc_init()
 * leaves it (gc.threshold() still sets one). */
#define MICROPY_PORT_INIT_FUNC \
	do { \
		esdr_port_init(); \
		MP_STATE_MEM(gc_alloc_threshold) = (size_t)-1; \
	} while (0)
#define MICROPY_PORT_DEINIT_FUNC            esdr_port_deinit()

/* The network stack is only there for the Wi-Fi driver, which brings the radio up (the port
 * tests the socket module with #ifdef). */
#undef MICROPY_PY_SOCKET

/*
 * The Wi-Fi driver selects THREAD_CUSTOM_DATA, which turns the port's _thread on: 20 KiB of
 * stacks the DRAM image has no room for. hashlib's sha256 collides with the Wi-Fi
 * supplicant's (sha256_init).
 */
#undef MICROPY_PY_THREAD
#undef MICROPY_PY_THREAD_GIL
#undef MICROPY_PY_THREAD_GIL_VM_DIVISOR
#undef MICROPY_PY_HASHLIB
#define MICROPY_PY_HASHLIB                  (0)
```

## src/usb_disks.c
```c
/*
 * SPDX-License-Identifier: GPL-3.0-or-later
 *
 * The volumes on USB: MSC LUN 0 is the internal FAT volume (disk FLASH), LUN 1 the SD card
 * (disk SD). The LUNs reach the disks through proxies that report no medium while the board
 * writes a volume (usb_disk_claim()): the host drops what it cached and reads the volume
 * afresh when it comes back. Zephyr's MSC has no other way to tell the host that the
 * medium changed (no unit attention), and two writers on one FAT corrupt it. The board's
 * own reads are not guarded: after the host changed a volume, a claim and release (or a
 * soft reset) refreshes the board's view.
 */

#include <errno.h>
#include <string.h>

#include <zephyr/drivers/disk.h>
#include <zephyr/fs/fs.h>
#include <zephyr/init.h>
#include <zephyr/kernel.h>
#include <zephyr/storage/disk_access.h>
#include <zephyr/usb/class/usbd_msc.h>

#include <ff.h>

#include "usb_disks.h"

/* Long enough for the host's media poll (udisks: every 2 s) to see the medium gone. */
#define HIDE_MIN_MS 3000

/* Boards without a card slot have no "/SD:" volume (sd_fs). */
#define HAS_SD DT_NODE_EXISTS(DT_NODELABEL(sd_fs))

FS_FSTAB_DECLARE_ENTRY(DT_NODELABEL(flash_fs));
#if HAS_SD
FS_FSTAB_DECLARE_ENTRY(DT_NODELABEL(sd_fs));
#endif

struct usb_disk {
	struct disk_info info;
	const char *target;
	struct fs_mount_t *mount;
	struct k_mutex lock;
	bool shared;
	int64_t hidden_at;
};

static struct usb_disk *to_usb_disk(struct disk_info *disk)
{
	return CONTAINER_OF(disk, struct usb_disk, info);
}

/*
 * Only the board initialises the disks (mounting them): an init from the USB thread as well
 * would race it. Until the board has mounted a volume, the host sees no medium.
 */
static int proxy_init(struct disk_info *disk)
{
	ARG_UNUSED(disk);
	return 0;
}

static int proxy_status(struct disk_info *disk)
{
	struct usb_disk *u = to_usb_disk(disk);

	if (!u->shared) {
		return DISK_STATUS_NOMEDIA;
	}
	return disk_access_status(u->target);
}

static int proxy_read(struct disk_info *disk, uint8_t *buf, uint32_t sector, uint32_t count)
{
	struct usb_disk *u = to_usb_disk(disk);
	int ret = -EIO;

	k_mutex_lock(&u->lock, K_FOREVER);
	if (u->shared && disk_access_status(u->target) == DISK_STATUS_OK) {
		ret = disk_access_read(u->target, buf, sector, count);
	}
	k_mutex_unlock(&u->lock);
	return ret;
}

static int proxy_write(struct disk_info *disk, const uint8_t *buf, uint32_t sector,
		       uint32_t count)
{
	struct usb_disk *u = to_usb_disk(disk);
	int ret = -EIO;

	k_mutex_lock(&u->lock, K_FOREVER);
	if (u->shared && disk_access_status(u->target) == DISK_STATUS_OK) {
		ret = disk_access_write(u->target, buf, sector, count);
	}
	k_mutex_unlock(&u->lock);
	return ret;
}

static int proxy_ioctl(struct disk_info *disk, uint8_t cmd, void *buf)
{
	switch (cmd) {
	case DISK_IOCTL_GET_SECTOR_COUNT:
	case DISK_IOCTL_GET_SECTOR_SIZE:
	case DISK_IOCTL_GET_ERASE_BLOCK_SZ:
	case DISK_IOCTL_CTRL_SYNC:
		return disk_access_ioctl(to_usb_disk(disk)->target, cmd, buf);
	default:
		/* Init, deinit and power stay with the board's mounts. */
		return 0;
	}
}

static const struct disk_operations proxy_ops = {
	.init = proxy_init,
	.status = proxy_status,
	.read = proxy_read,
	.write = proxy_write,
	.ioctl = proxy_ioctl,
};

static struct usb_disk disks[] = {
	{
		.info = {.name = "UFLASH", .ops = &proxy_ops},
		.target = "FLASH",
		.mount = &FS_FSTAB_ENTRY(DT_NODELABEL(flash_fs)),
		.shared = true,
	},
#if HAS_SD
	{
		.info = {.name = "USD", .ops = &proxy_ops},
		.target = "SD",
		.mount = &FS_FSTAB_ENTRY(DT_NODELABEL(sd_fs)),
		.shared = true,
	},
#endif
};

/* Sorted by id: LUN 0 FLASH, LUN 1 SD. */
USBD_DEFINE_MSC_LUN(a_flash, "UFLASH", "ESP-SDR", "FLASH", "1.0");
#if HAS_SD
USBD_DEFINE_MSC_LUN(b_sd, "USD", "ESP-SDR", "SD card", "1.0");
#endif

static struct usb_disk *find(const char *mnt)
{
	ARRAY_FOR_EACH_PTR(disks, u) {
		if (strcmp(u->mount->mnt_point, mnt) == 0) {
			return u;
		}
	}
	return NULL;
}

int usb_disk_claim(const char *mnt)
{
	struct usb_disk *u = find(mnt);

	if (u == NULL) {
		return -ENOENT;
	}
	k_mutex_lock(&u->lock, K_FOREVER);
	if (u->shared) {
		u->shared = false;
		u->hidden_at = k_uptime_get();
	}
	k_mutex_unlock(&u->lock);
	/*
	 * No host access from here on: drop what FatFs cached and read the volume afresh. A
	 * remount through the fs API would power the disk off and on, and the SD card does not
	 * always come back from that; registering the work area again keeps the disk as it is.
	 */
	return f_mount((FATFS *)u->mount->fs_data, &u->mount->mnt_point[1], 1) == FR_OK ? 0 : -EIO;
}

int usb_disk_release(const char *mnt)
{
	struct usb_disk *u = find(mnt);
	int64_t wait;

	if (u == NULL) {
		return -ENOENT;
	}
	(void)disk_access_ioctl(u->target, DISK_IOCTL_CTRL_SYNC, NULL);
	wait = u->hidden_at + HIDE_MIN_MS - k_uptime_get();
	if (wait > 0) {
		k_msleep((int32_t)wait);
	}
	k_mutex_lock(&u->lock, K_FOREVER);
	u->shared = true;
	k_mutex_unlock(&u->lock);
	return 0;
}

bool usb_disk_shared(const char *mnt)
{
	struct usb_disk *u = find(mnt);

	return u != NULL && u->shared;
}

static int usb_disks_init(void)
{
	ARRAY_FOR_EACH_PTR(disks, u) {
		k_mutex_init(&u->lock);
		(void)disk_access_register(&u->info);
	}
	return 0;
}

/* Before USB starts (app_usb_init(), boot.c), whose MSC class looks the LUNs' disks up, and
 * before MicroPython mounts the volumes. */
SYS_INIT(usb_disks_init, APPLICATION, 0);
```

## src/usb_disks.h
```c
/*
 * SPDX-License-Identifier: GPL-3.0-or-later
 */

#ifndef USB_DISKS_H_
#define USB_DISKS_H_

#include <stdbool.h>

/*
 * Takes the volume at @p mnt ("/FLASH:" or "/SD:") from the USB host before the board writes
 * it: the host sees the medium removed, and the board re-reads the volume (the host may
 * have changed it). 0, -ENOENT for an unknown mount point, -EIO if the volume did not mount.
 */
int usb_disk_claim(const char *mnt);

/*
 * Gives the volume back to the host once the board's files on it are closed: syncs the disk
 * and shows the medium again, at the earliest some seconds after the claim so that the host's
 * media poll has seen it gone.
 */
int usb_disk_release(const char *mnt);

/* Whether the host sees the volume at @p mnt. */
bool usb_disk_shared(const char *mnt);

#endif /* USB_DISKS_H_ */
```
